# LargeDummyDevice register map
File version: 1.0
Registers are 32-bit, read-write, no defined reset value unless marked. A register's access mark holds for its fields unless they carry their own. Offsets are from the block's base; [hi:lo] are bit positions.

## PERIPHERAL_82
Base 0x40051000
0x04 REG_1 — Register 1
  [33:31] FIELD_11, [31] FIELD_18, [34:31] FIELD_21, [31:30] FIELD_5, [32:29] FIELD_19, [28:27] FIELD_7, [29:27] FIELD_15, [29:27] FIELD_26, [30:26] FIELD_14, [27:26] FIELD_28, [27:25] FIELD_23, [25:24] FIELD_3, [27:24] FIELD_30, [23] FIELD_31, [23:21] FIELD_4, [24:20] FIELD_8, [21:20] FIELD_17, [23:20] FIELD_20, [20] FIELD_24, [19] FIELD_1, [22:19] FIELD_22, [19:17] FIELD_10, [20:16] FIELD_6, [19:15] FIELD_9, [14:13] FIELD_12, [13:11] FIELD_25, [14:10] FIELD_27, [4] FIELD_2, [4:2] FIELD_13, [3:2] FIELD_29, [1:0] FIELD_16
0x08 REG_2 — Register 2
  [32:30] FIELD_13, [27:23] FIELD_3, [23:22] FIELD_7, [22:18] FIELD_8, [19:16] FIELD_6, [15] FIELD_2, [14] FIELD_4, [14] FIELD_11, [10:9] FIELD_5, [10:6] FIELD_1, [6:5] FIELD_12, [2] FIELD_9, [1] FIELD_10
0x0C REG_3 — Register 3
  [33:30] FIELD_22, [33:30] FIELD_31, [30:29] FIELD_7, [31:28] FIELD_23, [32:28] FIELD_24, [27:26] FIELD_16, [26] FIELD_25, [25:23] FIELD_27, [19] FIELD_1, [18] FIELD_21, [19:17] FIELD_29, [17:16] FIELD_12, [15] FIELD_9, [18:14] FIELD_17, [13:11] FIELD_18, [12:10] FIELD_8, [12:9] FIELD_3, [12:9] FIELD_28, [9:7] FIELD_13, [10:7] FIELD_15, [11:7] FIELD_20, [9:6] FIELD_5, [6] FIELD_6, [7:6] FIELD_11, [7:6] FIELD_14, [8:6] FIELD_30, [4] FIELD_10, [7:3] FIELD_4, [4:3] FIELD_26, [5:1] FIELD_2, [1:0] FIELD_19
0x10 REG_4 — Register 4
  [26:25] FIELD_4, [22:18] FIELD_3, [15:13] FIELD_2, [15:12] FIELD_1, [8:5] FIELD_5
0x14 REG_5 — Register 5
  [35:31] FIELD_14, [32:31] FIELD_16, [33:30] FIELD_3, [30] FIELD_6, [30] FIELD_15, [29:26] FIELD_4, [27:26] FIELD_8, [25] FIELD_18, [26:25] FIELD_22, [24:20] FIELD_19, [20] FIELD_23, [19] FIELD_5, [19:18] FIELD_24, [18:17] FIELD_11, [18:17] FIELD_20, [10] FIELD_10, [10:9] FIELD_9, [11:9] FIELD_12, [13:9] FIELD_21, [9:7] FIELD_25, [5:4] FIELD_13, [4:3] FIELD_2, [7:3] FIELD_7, [4:2] FIELD_1, [5:1] FIELD_17
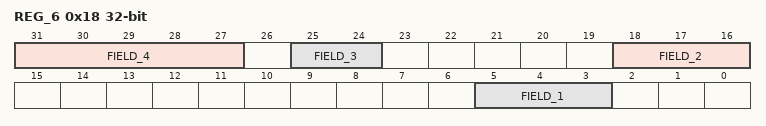
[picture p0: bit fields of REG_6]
0x18 REG_6 — Register 6
  [31:27] FIELD_4, [25:24] FIELD_3, [18:16] FIELD_2, [5:3] FIELD_1
0x1C REG_7 — Register 7
  [31:28] FIELD_9, [30:27] FIELD_3, [31:27] FIELD_24, [23] FIELD_20, [22] FIELD_23, [21] FIELD_1, [23:21] FIELD_5, [24:20] FIELD_15, [20:19] FIELD_10, [17] FIELD_2, [19:17] FIELD_18, [17:16] FIELD_6, [18:15] FIELD_12, [16:12] FIELD_17, [13:12] FIELD_21, [12:9] FIELD_16, [11:8] FIELD_19, [10:7] FIELD_11, [10:7] FIELD_13, [8:6] FIELD_7, [6:5] FIELD_4, [4:3] FIELD_8, [4:1] FIELD_14, [5:1] FIELD_22
0x20 REG_8 — Register 8
  [34:31] FIELD_1, [29:28] FIELD_14, [28:26] FIELD_18, [26:24] FIELD_7, [26:23] FIELD_15, [24:22] FIELD_11, [25:21] FIELD_8, [17:16] FIELD_13, [17:16] FIELD_21, [16:13] FIELD_16, [14:12] FIELD_5, [13:12] FIELD_22, [15:11] FIELD_19, [12:10] FIELD_12, [14:10] FIELD_17, [9] FIELD_23, [7:6] FIELD_3, [8:5] FIELD_20, [4] FIELD_6, [7:4] FIELD_9, [3:1] FIELD_2, [1] FIELD_4, [0] FIELD_10
0x24 REG_9 — Register 9
  [29:28] FIELD_4, [28:25] FIELD_11, [20:18] FIELD_2, [22:18] FIELD_13, [19:16] FIELD_6, [17:15] FIELD_5, [14:11] FIELD_14, [11:10] FIELD_3, [6] FIELD_8, [9:6] FIELD_10, [5:3] FIELD_7, [7:3] FIELD_12, [4:2] FIELD_1, [5:2] FIELD_9, [4:2] FIELD_15
0x28 REG_10 — Register 10
  [33:31] FIELD_3, [34:31] FIELD_7, [32:31] FIELD_17, [30:29] FIELD_8, [32:29] FIELD_21, [31:28] FIELD_10, [28:27] FIELD_2, [28:26] FIELD_14, [28:25] FIELD_18, [27:23] FIELD_4, [23:21] FIELD_15, [22:18] FIELD_1, [19:18] FIELD_12, [22:18] FIELD_25, [17] FIELD_23, [20:17] FIELD_30, [19:16] FIELD_29, [18:15] FIELD_24, [16:13] FIELD_13, [14:13] FIELD_31, [13] FIELD_32, [12] FIELD_9, [16:12] FIELD_20, [12:11] FIELD_28, [12:10] FIELD_6, [10] FIELD_22, [10:9] FIELD_5, [5:4] FIELD_19, [7:4] FIELD_26, [5:2] FIELD_11, [4:2] FIELD_16, [3:2] FIELD_27
0x2C REG_11 — Register 11
  [31:29] FIELD_6, [32:29] FIELD_9, [29] FIELD_13, [28] FIELD_2, [28:26] FIELD_7, [26:25] FIELD_23, [27:23] FIELD_16, [24:22] FIELD_1, [24:22] FIELD_8, [23:21] FIELD_25, [20] FIELD_19, [23:20] FIELD_26, [20:19] FIELD_17, [21:18] FIELD_3, [17] FIELD_11, [21:17] FIELD_15, [16] FIELD_24, [14:10] FIELD_21, [10:9] FIELD_14, [7] FIELD_4, [10:7] FIELD_22, [8:5] FIELD_20, [8:4] FIELD_5, [5:4] FIELD_12, [4:3] FIELD_18, [0] FIELD_10
0x30 REG_12 — Register 12
  [32:31] FIELD_10, [32:31] FIELD_19, [31:30] FIELD_9, [28:27] FIELD_16, [26:25] FIELD_20, [26:24] FIELD_17, [23] FIELD_18, [21:18] FIELD_11, [18:17] FIELD_8, [19:16] FIELD_3, [16:13] FIELD_22, [11] FIELD_2, [13:11] FIELD_5, [15:11] FIELD_23, [11:10] FIELD_15, [10:8] FIELD_14, [10:7] FIELD_1, [8:7] FIELD_21, [9:6] FIELD_4, [9:6] FIELD_6, [8:5] FIELD_13, [5:4] FIELD_7, [4:2] FIELD_12
0x34 REG_13 — Register 13
  [24:22] FIELD_8, [22:18] FIELD_5, [18:17] FIELD_6, [18:15] FIELD_3, [15:12] FIELD_1, [14:12] FIELD_4, [11:10] FIELD_9, [12:9] FIELD_2, [6:2] FIELD_7
